# STM32H573 register map
File version: 0.4
CPU: CM33 r0p0, little endian, MPU, FPU, 4 interrupt priority bits
Registers are 32-bit, read-write, reset 0x0 unless marked. A register's access mark holds for its fields unless they carry their own. Offsets are from the block's base; [hi:lo] are bit positions; {n}, {i} and the like mark numbered series.

## PWR — Power control
Base 0x44020800
Same registers: SEC_PWR 0x54020800
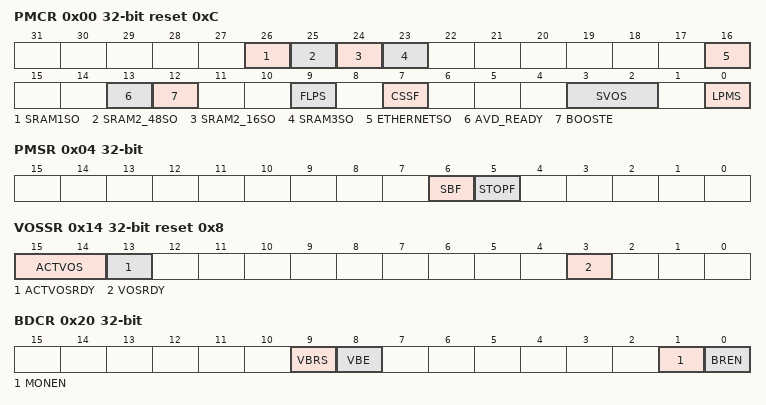
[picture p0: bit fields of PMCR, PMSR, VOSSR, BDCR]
0x00 PMCR reset 0xC — PWR power mode control register
  [26] SRAM1SO — AHB SRAM1 shut-off in Stop mode
  [25] SRAM2_48SO — AHB SRAM2 48-Kbyte shut-off in Stop mode.
  [24] SRAM2_16SO — AHB SRAM2 16-Kbyte shut-off in Stop mode.
  [23] SRAM3SO — AHB SRAM3 shut-off in Stop mode.
  [16] ETHERNETSO — ETHERNET RAM shut-off in Stop mode.
  [13] AVD_READY — analog voltage ready This bit is only used when the analog switch boost needs to be enabled (see BOOSTE bit). It must be set by software when the expected V<sub>DDA</sub> analog supply level is available. The correct analog supply level is indicated by the AVDO bit (PWR_VMSR register) after setting the AVDEN bit (PWR_VMCR register) and selecting the supply level to be monitored (ALS bits).
  [12] BOOSTE — analog switch V<sub>BOOST</sub> control This bit enables the booster to guarantee the analog switch AC performance when the V<sub>DD</sub> supply voltage is below 2.7 V (reduction of the total harmonic distortion to have the same switch performance over the full supply voltage range) The V<sub>DD</sub> supply voltage can be monitored through the PVD and the PLS bits.
  [9] FLPS — Flash memory low-power mode in Stop mode This bit is used to obtain the best trade-off between low-power consumption and restart time when exiting from Stop mode. When it is set, the Flash memory enters low-power mode when the CPU domain is in Stop mode. Note: When system enters stop mode with SVOS5 enabled, Flash memory is automatically forced in low-power mode.
  [7] CSSF — clear Standby and Stop flags (always read as 0) This bit is cleared to 0 by hardware.
  [3:2] SVOS — system Stop mode voltage scaling selection These bits control the V<sub>CORE</sub> voltage level in system Stop mode, to obtain the best trade-off between power consumption and performance.
  [0] LPMS — low-power mode selection This bit defines the Deepsleep mode.
0x04 PMSR ro — PWR status register
  [6] SBF — System standby flag This bit is set by hardware and cleared only by a POR or by setting the CSSF bit.
  [5] STOPF — Stop flag This bit is set by hardware and cleared only by any reset or by setting the CSSF bit.
0x10 VOSCR — PWR voltage scaling control register
  [5:4] VOS — voltage scaling selection according to performance These bits control the V<sub>CORE</sub> voltage level and allow to obtain the best trade-off between power consumption and performance: - In bypass mode, these bits must also be set according to the external provided core voltage level and related performance. - When increasing the performance, the voltage scaling must be changed before increasing the system frequency. - When decreasing performance, the system frequency must first be decreased before changing the voltage scaling.
0x14 VOSSR ro reset 0x8 — PWR voltage scaling status register
  [15:14] ACTVOS — voltage output scaling currently applied to V<sub>CORE</sub> This field provides the last VOS value.
  [13] ACTVOSRDY — Voltage level ready for currently used VOS
  [3] VOSRDY — Ready bit for V<sub>CORE</sub> voltage scaling output selection.
0x20 BDCR — PWR Backup domain control register
  [9] VBRS — V<sub>BAT</sub> charging resistor selection
  [8] VBE — V<sub>BAT</sub> charging enable Note: Reset only by POR,.
  [1] MONEN — Backup domain voltage and temperature monitoring enable
  [0] BREN — Backup RAM retention in Standby and V<sub>BAT</sub> modes When this bit set, the backup regulator (used to maintain the backup RAM content in Standby and V<sub>BAT</sub> modes) is enabled. If BREN is cleared, the backup regulator is switched off. The backup RAM can still be used in Run and Stop modes. However its content is lost in Standby and V<sub>BAT</sub> modes. If BREN is set, the application must wait till the backup regulator ready flag (BRRDY) is set to indicate that the data written into the SRAM is maintained in Standby and V<sub>BAT</sub> modes.
0x24 DBPCR — PWR Backup domain control register
  [0] DBP — Disable Backup domain write protection In reset state, all registers and SRAM in Backup domain are protected against parasitic write access. This bit must be set to enable write access to these registers.
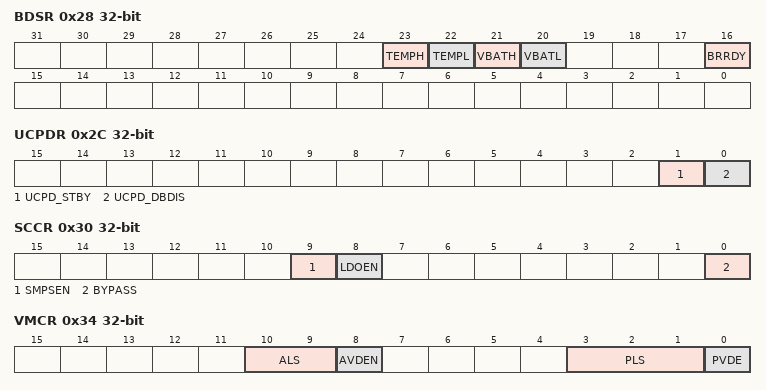
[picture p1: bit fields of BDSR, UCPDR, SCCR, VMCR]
0x28 BDSR ro — PWR Backup domain status register
  [23] TEMPH — temperature level monitoring versus high threshold
  [22] TEMPL — temperature level monitoring versus low threshold
  [21] VBATH — V<sub>BAT</sub> level monitoring versus high threshold
  [20] VBATL — V<sub>BAT</sub> level monitoring versus low threshold
  [16] BRRDY — backup regulator ready This bit is set by hardware to indicate that the backup regulator is ready.
0x2C UCPDR — PWR USB Type-C power delivery register
  [1] UCPD_STBY — USB Type-c and Power delivery Standby mode When set, this bit is used to memorize the UCPD configuration in Standby mode. This bit must be written to 1 just before entering Standby mode when using UCPD, and it must be written to 0 after exiting the standby mode and before writing any UCPD register.
  [0] UCPD_DBDIS — USB Type-C and power delivery dead battery disable After exiting reset, the USB Type-C “dead battery” behavior is enabled, which may have a pull-down effect on CC1 and CC2 pins. It is recommended to disable it in all case, either to stop this pull-down or to hand over control to the UCPD (which should therefore be initialized before doing the disable).
0x30 SCCR access per field (reset mask 0xFFFFF0FF) — PWR supply configuration control register
  [9] SMPSEN ro — SMPS enable The value is set by hardware when the package uses the SMPS regulator.
  [8] LDOEN ro — LDO enable The value is set by hardware when the package uses the LDO regulator.
  [0] BYPASS rw-once — power management unit bypass
0x34 VMCR — PWR voltage monitor control register
  [10:9] ALS — analog voltage detector (AVD) level selection These bits select the voltage threshold detected by the AVD.
  [8] AVDEN — peripheral voltage monitor on V<sub>DDA</sub> enable
  [3:1] PLS — programmable voltage detector (PVD) level selection These bits select the voltage threshold detected by the PVD.
  [0] PVDE — PVD enable
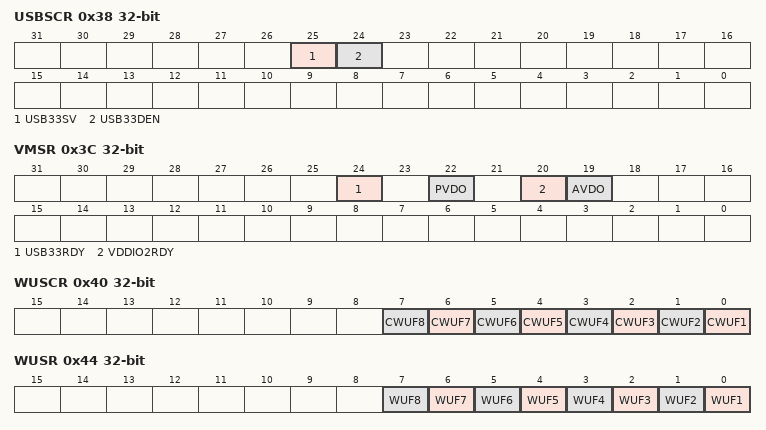
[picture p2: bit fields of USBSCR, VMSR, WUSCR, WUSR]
0x38 USBSCR — PWR USB supply control register
  [25] USB33SV — independent USB supply valid This bit is used to validate the V<sub>DDUSB</sub> supply for electrical and logical isolation purpose. Setting this bit is mandatory to use the USBFS peripheral. If V<sub>DDUSB</sub> is not always present in the application, the V<sub>DDUSB</sub> voltage monitor can be used to determine whether this supply is ready or not.
  [24] USB33DEN — V<sub>DDUSB</sub> voltage level detector enable
0x3C VMSR ro — PWR voltage monitor status register
  [24] USB33RDY — V<sub>DDUSB</sub> ready
  [22] PVDO — programmable voltage detect output This bit is set and cleared by hardware. It is valid only if the PVD has been enabled by the PVDE bit. Note: Since the PVD is disabled in Standby mode, this bit is equal to 0 after Standby or reset until the PVDE bit is set.
  [20] VDDIO2RDY — voltage detector output on V<sub>DDIO2</sub> This bit is set and cleared by hardware.
  [19] AVDO — analog voltage detector output on V<sub>DDA</sub> This bit is set and cleared by hardware. It is valid only if AVD on VDDA is enabled by the AVDEN bit. Note: Since the AVD is disabled in Standby mode, this bit is equal to 0 after standby or reset until the AVDEN bit is set.
0x40 WUSCR wo — PWR wakeup status clear register
  [n-1] CWUF{n} (n=1..8) — clear wakeup pin flag for WUFx These bits are always read as 0.
0x44 WUSR ro — PWR wakeup status register
  [n-1] WUF{n} (n=1..8) — wakeup pin WUFx flag This bit is set by hardware and cleared only by a RESET pin or by setting the CWUFx bit in PWR_WUSCR register.
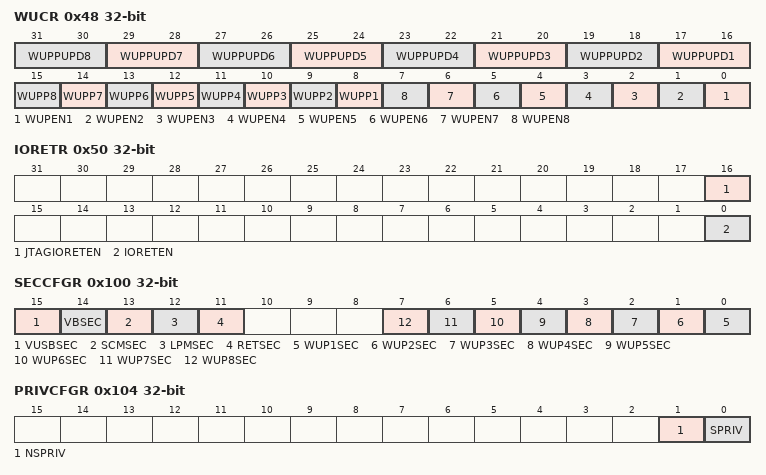
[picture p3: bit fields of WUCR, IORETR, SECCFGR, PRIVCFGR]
0x48 WUCR — PWR wakeup configuration register
  [2n+15:2n+14] WUPPUPD{n} (n=1..8) — wakeup pin pull configuration for WKUPx These bits define the I/O pad pull configuration used when WUPENx = 1. The associated GPIO port pull configuration must be set to the same value or to 00. The wakeup pin pull configuration is kept in Standby mode.
  [n+7] WUPP{n} (n=1..8) — wakeup pin polarity bit for WUPx These bits define the polarity used for event detection on WUPx external wakeup pin.
  [n-1] WUPEN{n} (n=1..8) — enable wakeup pin WUPx These bits are set and cleared by software. Note: an additional wakeup event is detected if WUPx pin is enabled (by setting the WUPENx bit) when WUPx pin level is already high when WUPPx selects rising edge, or low when WUPPx selects falling edge.
0x50 IORETR — PWR I/O retention register
  [16] JTAGIORETEN — IO retention enable for JTAG IOs when entering into standby mode, the output is sampled, and apply to the output IO during the standby power mode
  [0] IORETEN — IO retention enable: When entering into standby mode, the output is sampled, and apply to the output IO during the standby power mode. Note: the IO state is not retained if the DBG_STANDBY bit is set in DBGMCU_CR register.
0x100 SECCFGR — PWR security configuration register
  [15] VUSBSEC — voltage USB secure protection
  [14] VBSEC — backup domain secure protection
  [13] SCMSEC — supply configuration and monitoring secure protection.
  [12] LPMSEC — low-power modes secure protection
  [11] RETSEC — retention secure protection
  [n-1] WUP{n}SEC (n=1..8) — WUPx secure protection
0x104 PRIVCFGR — PWR privilege configuration register
  [1] NSPRIV — PWR non-secure functions privilege configuration Set and reset by software. This bit can be written only by privileged access, secure or non-secure.
  [0] SPRIV — PWR secure functions privilege configuration Set and reset by software. This bit can be written only by a secure privileged access.
